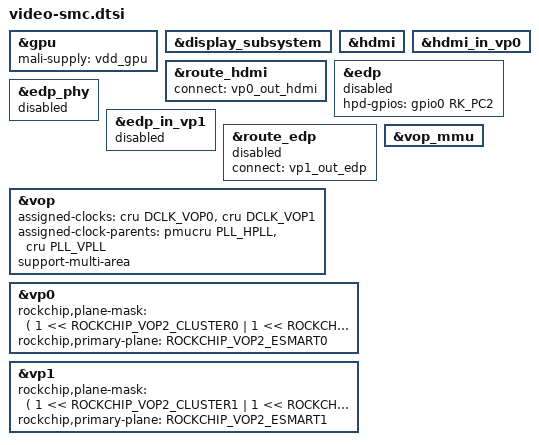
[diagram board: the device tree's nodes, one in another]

#include <dt-bindings/display/rockchip_vop.h>

&gpu {
	mali-supply = <&vdd_gpu>;
	status = "okay";
};

&display_subsystem {
	status = "okay";
};

//***************************************************************************************//

&hdmi {
	status = "okay";
};

&hdmi_in_vp0 {
	status = "okay";
};

&route_hdmi {
	status = "okay";
	connect = <&vp0_out_hdmi>;
};

//***************************************************************************************//

&edp {
/*
	CPU_DP_HDP
*/
	hpd-gpios = <&gpio0 RK_PC2 GPIO_ACTIVE_HIGH>;
	status = "disabled";
};

&edp_phy  {
	status = "disabled";
};

&edp_in_vp1 {
	status = "disabled";
};

&route_edp {
	status = "disabled";
	connect = <&vp1_out_edp>;
};

//***************************************************************************************//

&vop {
	status = "okay";
	assigned-clocks = <&cru DCLK_VOP0>, <&cru DCLK_VOP1>;
	assigned-clock-parents = <&pmucru PLL_HPLL>, <&cru PLL_VPLL>;
	support-multi-area;
	//disable-afbc-win;
};

&vop_mmu {
	status = "okay";
};

&vp0 {
	rockchip,plane-mask = <( 1 << ROCKCHIP_VOP2_CLUSTER0 | 1 << ROCKCHIP_VOP2_ESMART0 )>;
	rockchip,primary-plane = <ROCKCHIP_VOP2_ESMART0>;
//	cursor-win-id = <ROCKCHIP_VOP2_SMART0>;
};

&vp1 {
	rockchip,plane-mask = <( 1 << ROCKCHIP_VOP2_CLUSTER1 | 1 << ROCKCHIP_VOP2_ESMART1 )>;
	rockchip,primary-plane = <ROCKCHIP_VOP2_ESMART1>;
//	cursor-win-id = <ROCKCHIP_VOP2_SMART0>;
};

//***************************************************************************************//

